VERSION ""

NS_ :

BS_:

BU_: BMSMaster Converter CoolingBack CoolingLeft CoolingMotor CoolingRight Dashboard Engines JETSON LightsFR LightsFL LightsRR LightsRL MPPT Pedals RCD SafeState SensorFR SensorFL SensorRR SensorRL SmallBMS

BO_ 3221225472 VECTOR__INDEPENDENT_SIG_MSG: 0 Vector__XXX
 SG_ BMSMaster_MasterBatteryCurrent : 23|8@0+ (0.1465,300) [-300|300] "A" Vector__XXX
 SG_ BMSMaster_MasterBatteryVoltage : 15|8@0+ (0.0059,12) [63|87] "V" Vector__XXX
 SG_ BMSMaster_MasterBatteryTemperatur : 47|8@0+ (0.024,50) [0|100] "C" Vector__XXX
 SG_ BMSMaster_ErrorCodeBL : 23|8@0+ (1,0) [256|65535] "" Vector__XXX

BO_ 1952 LightsRL_NODE: 8 LightsRL

BO_ 1920 LightsRR_NODE: 8 LightsRR

BO_ 1888 LightsFL_NODE: 8 LightsFL

BO_ 1856 LightsFR_NODE: 8 LightsFR

BO_ 1696 SensorRL_NODE: 8 SensorRL

BO_ 1664 SensorRR_NODE: 8 SensorRR

BO_ 1632 SensorFL_NODE: 8 SensorFL

BO_ 1600 SensorFR_NODE: 8 SensorFR

BO_ 1472 LowVoltConverter_NODE: 8 Converter

BO_ 1344 CoolingMotor_NODE: 8 CoolingMotor

BO_ 1312 CoolingRight_NODE: 8 CoolingRight

BO_ 1280 CoolingLeft_NODE: 8 CoolingLeft

BO_ 1248 CoolingBack_NODE: 8 CoolingBack

BO_ 1120 MPPT_NODE: 8 MPPT

BO_ 992 Dashboard_NODE: 8 Dashboard

BO_ 864 SmallBMS_NODE: 8 SmallBMS

BO_ 192 RCD_STATIC_NODE: 8 RCD

BO_ 128 BMSMaster_NODE: 3 BMSMaster
 SG_ BMSMaster_ErrorCode : 15|16@0+ (1,0) [0|255] "" Vector__XXX
 SG_ BMSMaster_SafeState : 0|1@0+ (1,0) [0|1] "" Vector__XXX

BO_ 64 Pedals_NODE: 8 Pedals

BO_ 512 JETSON_STATIC_NODE: 8 JETSON

BO_ 0 SafeState_NODE: 8 SafeState

BO_ 1983 LightsRL_END: 8 LightsRL

BO_ 1727 SensorRL_END: 8 SensorRL

BO_ 1951 LightsRR_END: 8 LightsRR

BO_ 31 SafeState_END: 8 SafeState

BO_ 95 Pedals_END: 8 Pedals

BO_ 159 BMSMaster_END: 8 BMSMaster

BO_ 223 RCD_STATIC_END: 8 RCD

BO_ 543 JETSON_STATIC_END: 8 JETSON

BO_ 895 SmallBMS_END: 8 SmallBMS

BO_ 1503 LowVoltConverter_END: 8 Converter

BO_ 1279 CoolingBack_END: 8 CoolingBack

BO_ 1311 CoolingLeft_END: 8 CoolingLeft

BO_ 1375 CoolingMotor_END: 8 CoolingMotor

BO_ 1343 CoolingRight_END: 8 CoolingRight

BO_ 1023 Dashboard_END: 8 Dashboard

BO_ 1151 MPPT_END: 8 MPPT

BO_ 1653 SensorFL_END: 8 SensorFL

BO_ 1631 SensorFR_END: 8 SensorFR

BO_ 1695 SensorRR_END: 8 SensorRR

BO_ 1919 LightsFL_END: 8 LightsFL

BO_ 1887 LightsFR_END: 8 LightsFR

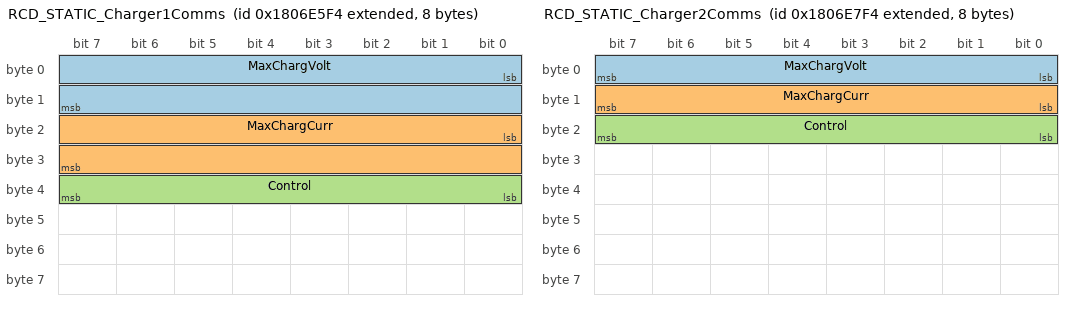
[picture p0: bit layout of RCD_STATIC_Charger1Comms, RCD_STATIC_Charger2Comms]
BO_ 2550588916 RCD_STATIC_Charger1Comms: 8 RCD
 SG_ MaxChargVolt : 0|16@1+ (1,0) [0|0] "V" Vector__XXX
 SG_ MaxChargCurr : 16|16@1+ (1,0) [0|0] "A" Vector__XXX
 SG_ Control : 32|8@1+ (1,0) [0|0] "" Vector__XXX

BO_ 2550589428 RCD_STATIC_Charger2Comms: 8 RCD
 SG_ MaxChargVolt : 0|8@1+ (1,0) [0|0] "" Vector__XXX
 SG_ MaxChargCurr : 8|8@1+ (1,0) [0|0] "" Vector__XXX
 SG_ Control : 16|8@1+ (1,0) [0|0] "" Vector__XXX

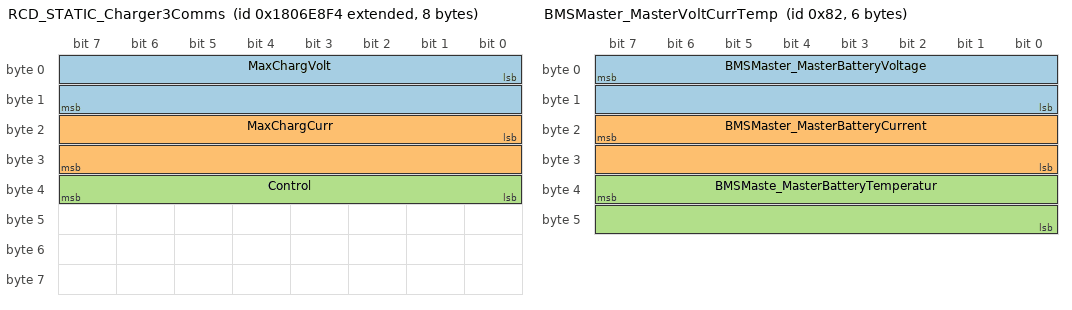
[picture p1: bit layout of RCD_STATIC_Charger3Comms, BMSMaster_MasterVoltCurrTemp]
BO_ 2550589684 RCD_STATIC_Charger3Comms: 8 RCD
 SG_ MaxChargVolt : 0|16@1+ (1,0) [0|0] "" Vector__XXX
 SG_ MaxChargCurr : 16|16@1+ (1,0) [0|0] "" Vector__XXX
 SG_ Control : 32|8@1+ (1,0) [0|0] "" Vector__XXX

BO_ 130 BMSMaster_MasterVoltCurrTemp: 6 BMSMaster
 SG_ BMSMaster_MasterBatteryVoltage : 7|16@0+ (0.0059,12) [63|87] "V" Vector__XXX
 SG_ BMSMaster_MasterBatteryCurrent : 23|16@0+ (0.1465,300) [-300|300] "A" Vector__XXX
 SG_ BMSMaste_MasterBatteryTemperatur : 39|16@0+ (0.024,50) [0|100] "C" Vector__XXX

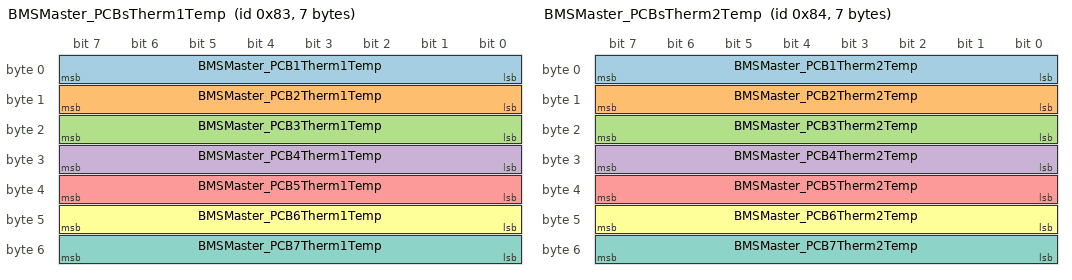
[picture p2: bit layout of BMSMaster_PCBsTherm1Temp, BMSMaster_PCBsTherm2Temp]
BO_ 131 BMSMaster_PCBsTherm1Temp: 7 BMSMaster
 SG_ BMSMaster_PCB1Therm1Temp : 7|8@0+ (0.39216,49.8039) [0|100] "�C" Vector__XXX
 SG_ BMSMaster_PCB2Therm1Temp : 15|8@0+ (0.39216,49.8039) [0|100] "�C" Vector__XXX
 SG_ BMSMaster_PCB3Therm1Temp : 23|8@0+ (0.39216,49.8039) [0|100] "�C" Vector__XXX
 SG_ BMSMaster_PCB4Therm1Temp : 31|8@0+ (0.39216,49.8039) [0|100] "�C" Vector__XXX
 SG_ BMSMaster_PCB5Therm1Temp : 39|8@0+ (0.39216,49.8039) [0|100] "�C" Vector__XXX
 SG_ BMSMaster_PCB6Therm1Temp : 47|8@0+ (0.39216,49.8039) [0|100] "�C" Vector__XXX
 SG_ BMSMaster_PCB7Therm1Temp : 55|8@0+ (0.39216,49.8039) [0|100] "�C" Vector__XXX

BO_ 132 BMSMaster_PCBsTherm2Temp: 7 BMSMaster
 SG_ BMSMaster_PCB1Therm2Temp : 7|8@0+ (0.39216,49.8039) [0|100] "�C" Vector__XXX
 SG_ BMSMaster_PCB2Therm2Temp : 15|8@0+ (0.39216,49.8039) [0|100] "�C" Vector__XXX
 SG_ BMSMaster_PCB3Therm2Temp : 23|8@0+ (0.39216,49.8039) [0|100] "�C" Vector__XXX
 SG_ BMSMaster_PCB4Therm2Temp : 31|8@0+ (0.39216,49.8039) [0|100] "�C" Vector__XXX
 SG_ BMSMaster_PCB5Therm2Temp : 39|8@0+ (0.39216,49.8039) [0|100] "�C" Vector__XXX
 SG_ BMSMaster_PCB6Therm2Temp : 47|8@0+ (0.39216,49.8039) [0|100] "�C" Vector__XXX
 SG_ BMSMaster_PCB7Therm2Temp : 55|8@0+ (0.39216,49.8039) [0|100] "�C" Vector__XXX

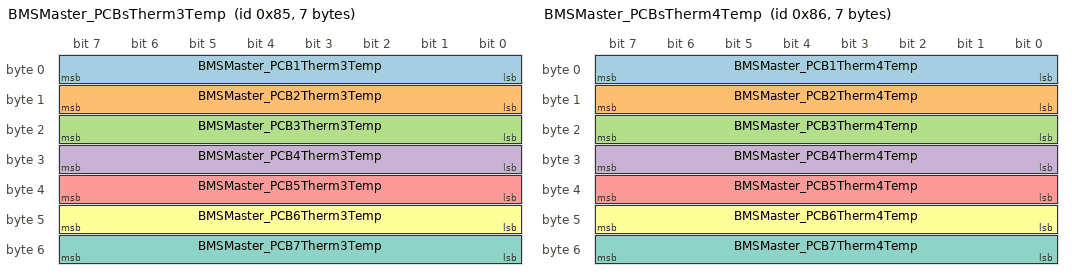
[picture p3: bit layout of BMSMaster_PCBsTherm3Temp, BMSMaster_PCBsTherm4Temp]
BO_ 133 BMSMaster_PCBsTherm3Temp: 7 BMSMaster
 SG_ BMSMaster_PCB1Therm3Temp : 7|8@0+ (0.39216,49) [0|100] "�C" Vector__XXX
 SG_ BMSMaster_PCB2Therm3Temp : 15|8@0+ (0.39216,49) [0|100] "�C" Vector__XXX
 SG_ BMSMaster_PCB3Therm3Temp : 23|8@0+ (0.39216,49) [0|100] "�C" Vector__XXX
 SG_ BMSMaster_PCB4Therm3Temp : 31|8@0+ (0.39216,49) [0|100] "�C" Vector__XXX
 SG_ BMSMaster_PCB5Therm3Temp : 39|8@0+ (0.39216,49) [0|100] "�C" Vector__XXX
 SG_ BMSMaster_PCB6Therm3Temp : 47|8@0+ (0.39216,49) [0|100] "�C" Vector__XXX
 SG_ BMSMaster_PCB7Therm3Temp : 55|8@0+ (0.39216,49) [0|100] "�C" Vector__XXX

BO_ 134 BMSMaster_PCBsTherm4Temp: 7 BMSMaster
 SG_ BMSMaster_PCB1Therm4Temp : 7|8@0+ (0.39216,49.8039) [0|100] "�C" Vector__XXX
 SG_ BMSMaster_PCB2Therm4Temp : 15|8@0+ (0.39216,49.8039) [0|100] "�C" Vector__XXX
 SG_ BMSMaster_PCB3Therm4Temp : 23|8@0+ (0.39216,49.8039) [0|100] "�C" Vector__XXX
 SG_ BMSMaster_PCB4Therm4Temp : 31|8@0+ (0.39216,49.8039) [0|100] "�C" Vector__XXX
 SG_ BMSMaster_PCB5Therm4Temp : 39|8@0+ (0.39216,49.8039) [0|100] "�C" Vector__XXX
 SG_ BMSMaster_PCB6Therm4Temp : 47|8@0+ (0.39216,49.8039) [0|100] "�C" Vector__XXX
 SG_ BMSMaster_PCB7Therm4Temp : 55|8@0+ (0.39216,49.8039) [0|100] "�C" Vector__XXX

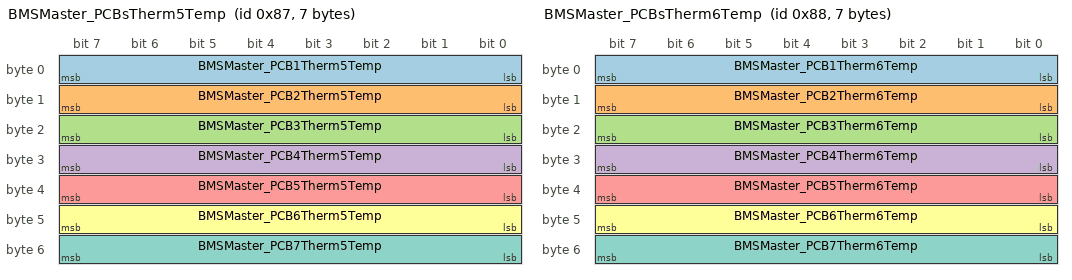
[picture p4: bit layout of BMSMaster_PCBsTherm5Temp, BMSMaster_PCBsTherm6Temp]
BO_ 135 BMSMaster_PCBsTherm5Temp: 7 BMSMaster
 SG_ BMSMaster_PCB1Therm5Temp : 7|8@0+ (0.39216,49.8039) [0|100] "�C" Vector__XXX
 SG_ BMSMaster_PCB2Therm5Temp : 15|8@0+ (0.39216,49.8039) [0|100] "�C" Vector__XXX
 SG_ BMSMaster_PCB3Therm5Temp : 23|8@0+ (0.39216,49.8039) [0|100] "�C" Vector__XXX
 SG_ BMSMaster_PCB4Therm5Temp : 31|8@0+ (0.39216,49.8039) [0|100] "�C" Vector__XXX
 SG_ BMSMaster_PCB5Therm5Temp : 39|8@0+ (0.39216,49.8039) [0|100] "�C" Vector__XXX
 SG_ BMSMaster_PCB6Therm5Temp : 47|8@0+ (0.39216,49.8039) [0|100] "�C" Vector__XXX
 SG_ BMSMaster_PCB7Therm5Temp : 55|8@0+ (0.39216,49.8039) [0|100] "�C" Vector__XXX

BO_ 136 BMSMaster_PCBsTherm6Temp: 7 BMSMaster
 SG_ BMSMaster_PCB1Therm6Temp : 7|8@0+ (0.39216,49.8039) [0|100] "�C" Vector__XXX
 SG_ BMSMaster_PCB2Therm6Temp : 15|8@0+ (0.39216,49.8039) [0|100] "�C" Vector__XXX
 SG_ BMSMaster_PCB3Therm6Temp : 23|8@0+ (0.39216,49.8039) [0|100] "�C" Vector__XXX
 SG_ BMSMaster_PCB4Therm6Temp : 31|8@0+ (0.39216,49.8039) [0|100] "�C" Vector__XXX
 SG_ BMSMaster_PCB5Therm6Temp : 39|8@0+ (0.39216,49.8039) [0|100] "�C" Vector__XXX
 SG_ BMSMaster_PCB6Therm6Temp : 47|8@0+ (0.39216,49.8039) [0|100] "�C" Vector__XXX
 SG_ BMSMaster_PCB7Therm6Temp : 55|8@0+ (0.39216,49.8039) [0|100] "�C" Vector__XXX

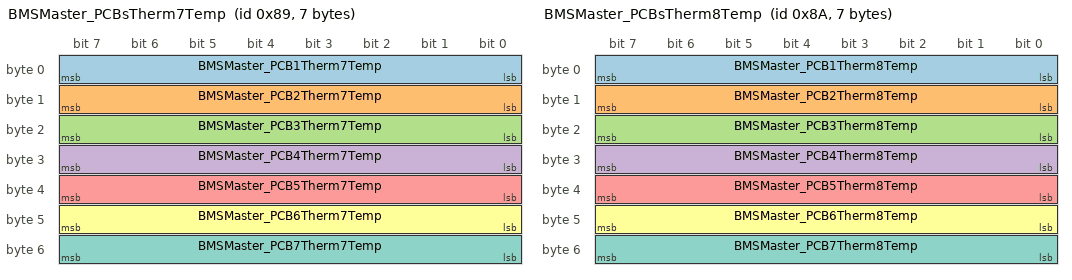
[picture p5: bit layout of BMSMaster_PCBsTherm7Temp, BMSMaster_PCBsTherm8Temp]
BO_ 137 BMSMaster_PCBsTherm7Temp: 7 BMSMaster
 SG_ BMSMaster_PCB1Therm7Temp : 7|8@0+ (0.39216,49) [0|100] "�C" Vector__XXX
 SG_ BMSMaster_PCB2Therm7Temp : 15|8@0+ (0.39216,49.8039) [0|100] "�C" Vector__XXX
 SG_ BMSMaster_PCB3Therm7Temp : 23|8@0+ (0.39216,49.8039) [0|100] "�C" Vector__XXX
 SG_ BMSMaster_PCB4Therm7Temp : 31|8@0+ (0.39216,49.8039) [0|100] "�C" Vector__XXX
 SG_ BMSMaster_PCB5Therm7Temp : 39|8@0+ (0.39216,49.8039) [0|100] "�C" Vector__XXX
 SG_ BMSMaster_PCB6Therm7Temp : 47|8@0+ (0.39216,49.8039) [0|100] "�C" Vector__XXX
 SG_ BMSMaster_PCB7Therm7Temp : 55|8@0+ (0.39216,49.8039) [0|100] "�C" Vector__XXX

BO_ 138 BMSMaster_PCBsTherm8Temp: 7 BMSMaster
 SG_ BMSMaster_PCB1Therm8Temp : 7|8@0+ (0.39216,49) [0|100] "�C" Vector__XXX
 SG_ BMSMaster_PCB2Therm8Temp : 15|8@0+ (0.39216,49) [0|100] "�C" Vector__XXX
 SG_ BMSMaster_PCB3Therm8Temp : 23|8@0+ (0.39216,49) [0|100] "�C" Vector__XXX
 SG_ BMSMaster_PCB4Therm8Temp : 31|8@0+ (0.39216,49) [0|100] "�C" Vector__XXX
 SG_ BMSMaster_PCB5Therm8Temp : 39|8@0+ (0.39216,49) [0|100] "�C" Vector__XXX
 SG_ BMSMaster_PCB6Therm8Temp : 47|8@0+ (0.39216,49) [0|100] "�C" Vector__XXX
 SG_ BMSMaster_PCB7Therm8Temp : 55|8@0+ (0.39216,49) [0|100] "�C" Vector__XXX

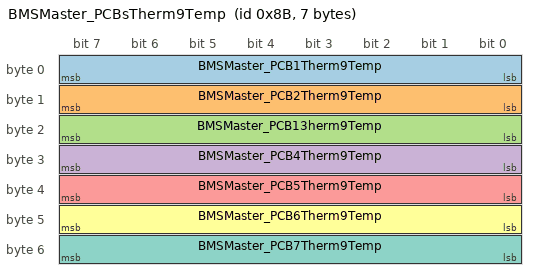
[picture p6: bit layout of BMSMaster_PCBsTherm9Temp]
BO_ 139 BMSMaster_PCBsTherm9Temp: 7 BMSMaster
 SG_ BMSMaster_PCB1Therm9Temp : 7|8@0+ (0.39216,49) [0|100] "�C" Vector__XXX
 SG_ BMSMaster_PCB2Therm9Temp : 15|8@0+ (0.39216,49) [0|100] "�C" Vector__XXX
 SG_ BMSMaster_PCB13herm9Temp : 23|8@0+ (0.39216,49) [0|100] "�C" Vector__XXX
 SG_ BMSMaster_PCB4Therm9Temp : 31|8@0+ (0.39216,49) [0|100] "�C" Vector__XXX
 SG_ BMSMaster_PCB5Therm9Temp : 39|8@0+ (0.39216,49) [0|100] "�C" Vector__XXX
 SG_ BMSMaster_PCB6Therm9Temp : 47|8@0+ (0.39216,49) [0|100] "�C" Vector__XXX
 SG_ BMSMaster_PCB7Therm9Temp : 55|8@0+ (0.39216,49) [0|100] "�C" Vector__XXX

CM_ BO_ 0 "
";
CM_ SG_ 2550588916 MaxChargVolt ".1V/byte offset:0 e.g. Vset=3201, its corresponding 320.1V";
CM_ SG_ 2550588916 MaxChargCurr ".1A/byte offset:0 e.g. Iset=582, its corresponding 58.2A";
CM_ SG_ 2550589428 MaxChargVolt ".1V/byte offset:0 e.g. Vset=3201, its corresponding 320.1V";
CM_ SG_ 2550589428 MaxChargCurr ".1A/byte offset:0 e.g. Iset=582, its corresponding 58.2A";
CM_ SG_ 2550589684 MaxChargVolt ".1V/byte offset:0 e.g. Vset=3201, its corresponding 320.1V";
CM_ SG_ 2550589684 MaxChargCurr ".1A/byte offset:0 e.g. Iset=582, its corresponding 58.2A";
VAL_ 2550588916 Control 1 "Stop charging" 0 "Start charging" ;
VAL_ 2550589428 Control 0 "Start charging" 1 "Stop charging" ;
VAL_ 2550589684 Control 1 "Stop charging" 0 "Start charging" ;
CM_ SG_ 130 BMSMaster_MasterBatteryVoltage "Master battery Voltage MSB value which is read by ADC embedded in stm32 core on BMS Masster board";
CM_ SG_ 130 BMSMaster_MasterBatteryCurrent "Master battery Current LSB value which is read by ADC embedded in stm32 core on BMS Masster board";
CM_ SG_ 130 BMSMaste_MasterBatteryTemperatur "Master battery Temperature MSB value which is read by ADC embedded in stm32 core on BMS Masster board";
